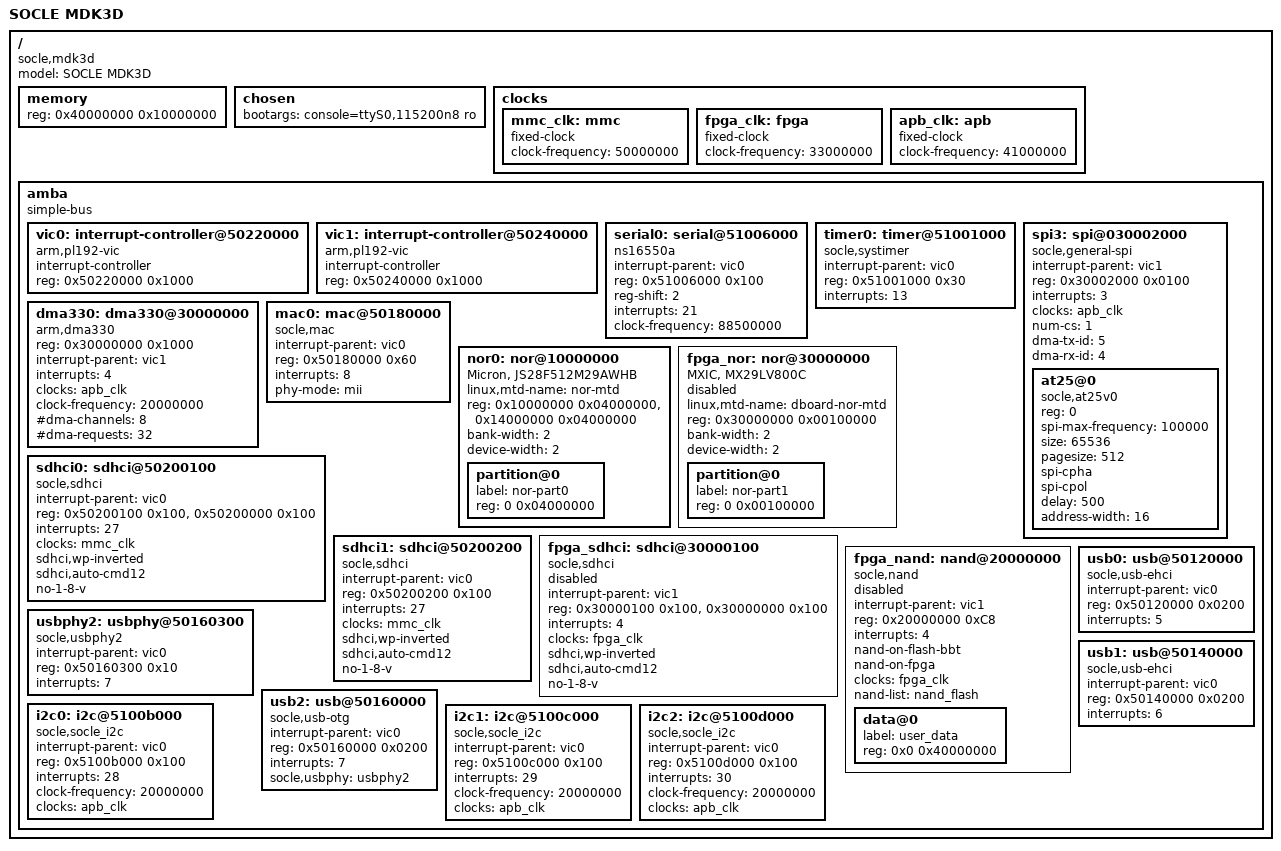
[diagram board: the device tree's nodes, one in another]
/dts-v1/;

/include/ "skeleton.dtsi"
/include/ "socle-nand.dtsi"

/ {
	model = "SOCLE MDK3D";
	compatible = "socle,mdk3d";
	#address-cells = <1>;
	#size-cells = <1>;

	memory {
		device_type = "memory";
		reg = <0x40000000 0x10000000>;
	};

	chosen {
		bootargs = "console=ttyS0,115200n8 ro";
	};

	clocks {
		mmc_clk: mmc {
			compatible = "fixed-clock";
			#clock-cells = <0>;
			clock-frequency = <50000000>;
		};

		fpga_clk: fpga {
			compatible = "fixed-clock";
			#clock-cells = <0>;
			clock-frequency = <33000000>;
		};
		apb_clk: apb {
			compatible = "fixed-clock";
			#clock-cells = <0>;
			clock-frequency = <41000000>;
		};
	};

	amba {
		compatible = "simple-bus";
		#address-cells = <1>;
		#size-cells = <1>;
		ranges;

		vic0: interrupt-controller@50220000 {
			compatible = "arm,pl192-vic";
			#interrupt-cells = <1>;
			interrupt-controller;
			reg = <0x50220000 0x1000>;
		};

		vic1: interrupt-controller@50240000 {
			compatible = "arm,pl192-vic";
			#interrupt-cells = <1>;
			interrupt-controller;
			reg = <0x50240000 0x1000>;
		};

		serial0: serial@51006000 {
			compatible = "ns16550a";
			interrupt-parent = <&vic0>;
			reg = <0x51006000 0x100>;
			reg-shift = <2>;
			interrupts = <21>;
			clock-frequency= <88500000>;
		};

		timer0: timer@51001000 {
			compatible = "socle,systimer";
			interrupt-parent = <&vic0>;
			reg = <0x51001000 0x30>;
			interrupts = <13>;
		};

		spi3: spi@030002000 {
			compatible = "socle,general-spi";
			#address-cells = <1>;
			#size-cells = <0>;
			interrupt-parent = <&vic1>;
			reg = <0x30002000 0x0100>;
			interrupts = <3>;
			clocks = <&apb_clk>;
			clock-names = "spi_mclk";
			num-cs = <1>;
			dma-tx-id = <5>;
			dma-rx-id = <4>;
			status = "okay";
		/*	dac0: dh2228@0 {
				compatible = "rohm,dh2228fv";
				reg = <0>;
				spi-max-frequency = <100000>;
			 };/**/
			at25@0 {
				compatible = "socle,at25v0";
				reg = <0>;
				spi-max-frequency = <100000>;
				size = <65536>;
				pagesize = <512>;
				spi-cpha;
				spi-cpol;
				delay = <500>;
				address-width = <16>;
			};/**/
			/*pinctrl-names = "default";
			pinctrl-0 = <&pinctrl_spi3>;*/
		};
		dma330: dma330@30000000 {
			compatible = "arm,dma330","arm,primecell";
			reg = <0x30000000 0x1000>;
			interrupt-parent = <&vic1>;
			interrupts = <4>;
			clocks = <&apb_clk>;
			clock-names = "apb_pclk";
			clock-frequency = <20000000>;
			#dma-cells = <1>;
			#dma-channels = <8>;
			#dma-requests = <32>;
			status = "okay";
		};

		mac0: mac@50180000 {
			compatible = "socle,mac";
			interrupt-parent = <&vic0>;
			reg = <0x50180000 0x60>;
			interrupts = <8>;
			phy-mode = "mii";
		};

		nor0: nor@10000000 {
			#address-cells = <1>;
			#size-cells = <1>;
			compatible = "Micron, JS28F512M29AWHB", "cfi-flash";
			linux,mtd-name = "nor-mtd";
			reg = <0x10000000 0x04000000>, <0x14000000 0x04000000>;
			bank-width = <2>;
			device-width = <2>;
			status = "okay";

			partition@0 {
				label = "nor-part0";
				reg = <0 0x04000000>;
			};
		};

		fpga_nor: nor@30000000 {
			#address-cells = <1>;
			#size-cells = <1>;
			compatible = "MXIC, MX29LV800C", "cfi-flash";
			linux,mtd-name = "dboard-nor-mtd";
			reg = <0x30000000 0x00100000>;
			bank-width = <2>;
			device-width = <2>;
			status = "disabled";

			partition@0 {
				label = "nor-part1";
				reg = <0 0x00100000>;
			};
		};

		sdhci0: sdhci@50200100 {
			compatible = "socle,sdhci", "socle,sdhci-2v09";
			interrupt-parent = <&vic0>;
			reg = <0x50200100 0x100>, <0x50200000 0x100>;
			interrupts = <27>;
			clocks = <&mmc_clk>;
			sdhci,wp-inverted;
			sdhci,auto-cmd12;
			no-1-8-v;
			status = "okay";
		};
		
		sdhci1: sdhci@50200200 {
			compatible = "socle,sdhci", "socle,sdhci-2v09";
			interrupt-parent = <&vic0>;
			reg = <0x50200200 0x100>;
			interrupts = <27>;
			clocks = <&mmc_clk>;
			sdhci,wp-inverted;
			sdhci,auto-cmd12;
			no-1-8-v;
			status = "okay";
		};
		
		fpga_sdhci: sdhci@30000100 {
			compatible = "socle,sdhci", "socle,sdhci-3v28";
			interrupt-parent = <&vic1>;
			reg = <0x30000100 0x100>, <0x30000000 0x100>;
			interrupts = <4>;
			clocks = <&fpga_clk>;
			sdhci,wp-inverted;
			sdhci,auto-cmd12;
			no-1-8-v;
			status = "disabled";
		};

		fpga_nand: nand@20000000 {
			compatible = "socle,nand";
			#address-cells = <1>;
			#size-cells = <1>;
			interrupt-parent = <&vic1>;
			reg = <0x20000000 0xC8>;
			interrupts = <4>;
			nand-on-flash-bbt;
			nand-on-fpga;
			clocks = <&fpga_clk>;
			nand-list = <&nand_flash>;
			status = "disabled";

			data@0 {
				label = "user_data";
				reg = <0x0 0x40000000>;
			};

		};

		usbphy2: usbphy@50160300 {
			compatible = "socle,usbphy2";
			interrupt-parent = <&vic0>;
			reg = <0x50160300 0x10>;
			interrupts = <7>;
		};
				
		usb0:	usb@50120000 {
			compatible = "socle,usb-ehci";
			interrupt-parent = <&vic0>;
			reg = <0x50120000 0x0200>;
			interrupts = <5>;
		};
		
		usb1:	usb@50140000 {
			compatible = "socle,usb-ehci";
			interrupt-parent = <&vic0>;
			reg = <0x50140000 0x0200>;
			interrupts = <6>;
		};
				
		usb2:	usb@50160000 {
			compatible = "socle,usb-otg";
			interrupt-parent = <&vic0>;
			reg = <0x50160000 0x0200>;
			interrupts = <7>;
			socle,usbphy = <&usbphy2>;
		};
		i2c0:	i2c@5100b000 {
			compatible = "socle,socle_i2c";
			interrupt-parent = <&vic0>;
			#address-cells = <1>;
			#size-cells = <0>;
			reg = <0x5100b000 0x100>;
			interrupts = <28>;
	                clock-frequency = <20000000>;
			clocks = <&apb_clk>;
			status = "okay";
		};
		i2c1:	i2c@5100c000 {
			compatible = "socle,socle_i2c";
			interrupt-parent = <&vic0>;
			#address-cells = <1>;
			#size-cells = <0>;
			reg = <0x5100c000 0x100>;
			interrupts = <29>;
	                clock-frequency = <20000000>;
			clocks = <&apb_clk>;
			status = "okay";
		};
		i2c2:	i2c@5100d000 {
			compatible = "socle,socle_i2c";
			interrupt-parent = <&vic0>;
			#address-cells = <1>;
			#size-cells = <0>;
			reg = <0x5100d000 0x100>;
			interrupts = <30>;
	                clock-frequency = <20000000>;
			clocks = <&apb_clk>;
			status = "okay";
		};

	};
};
